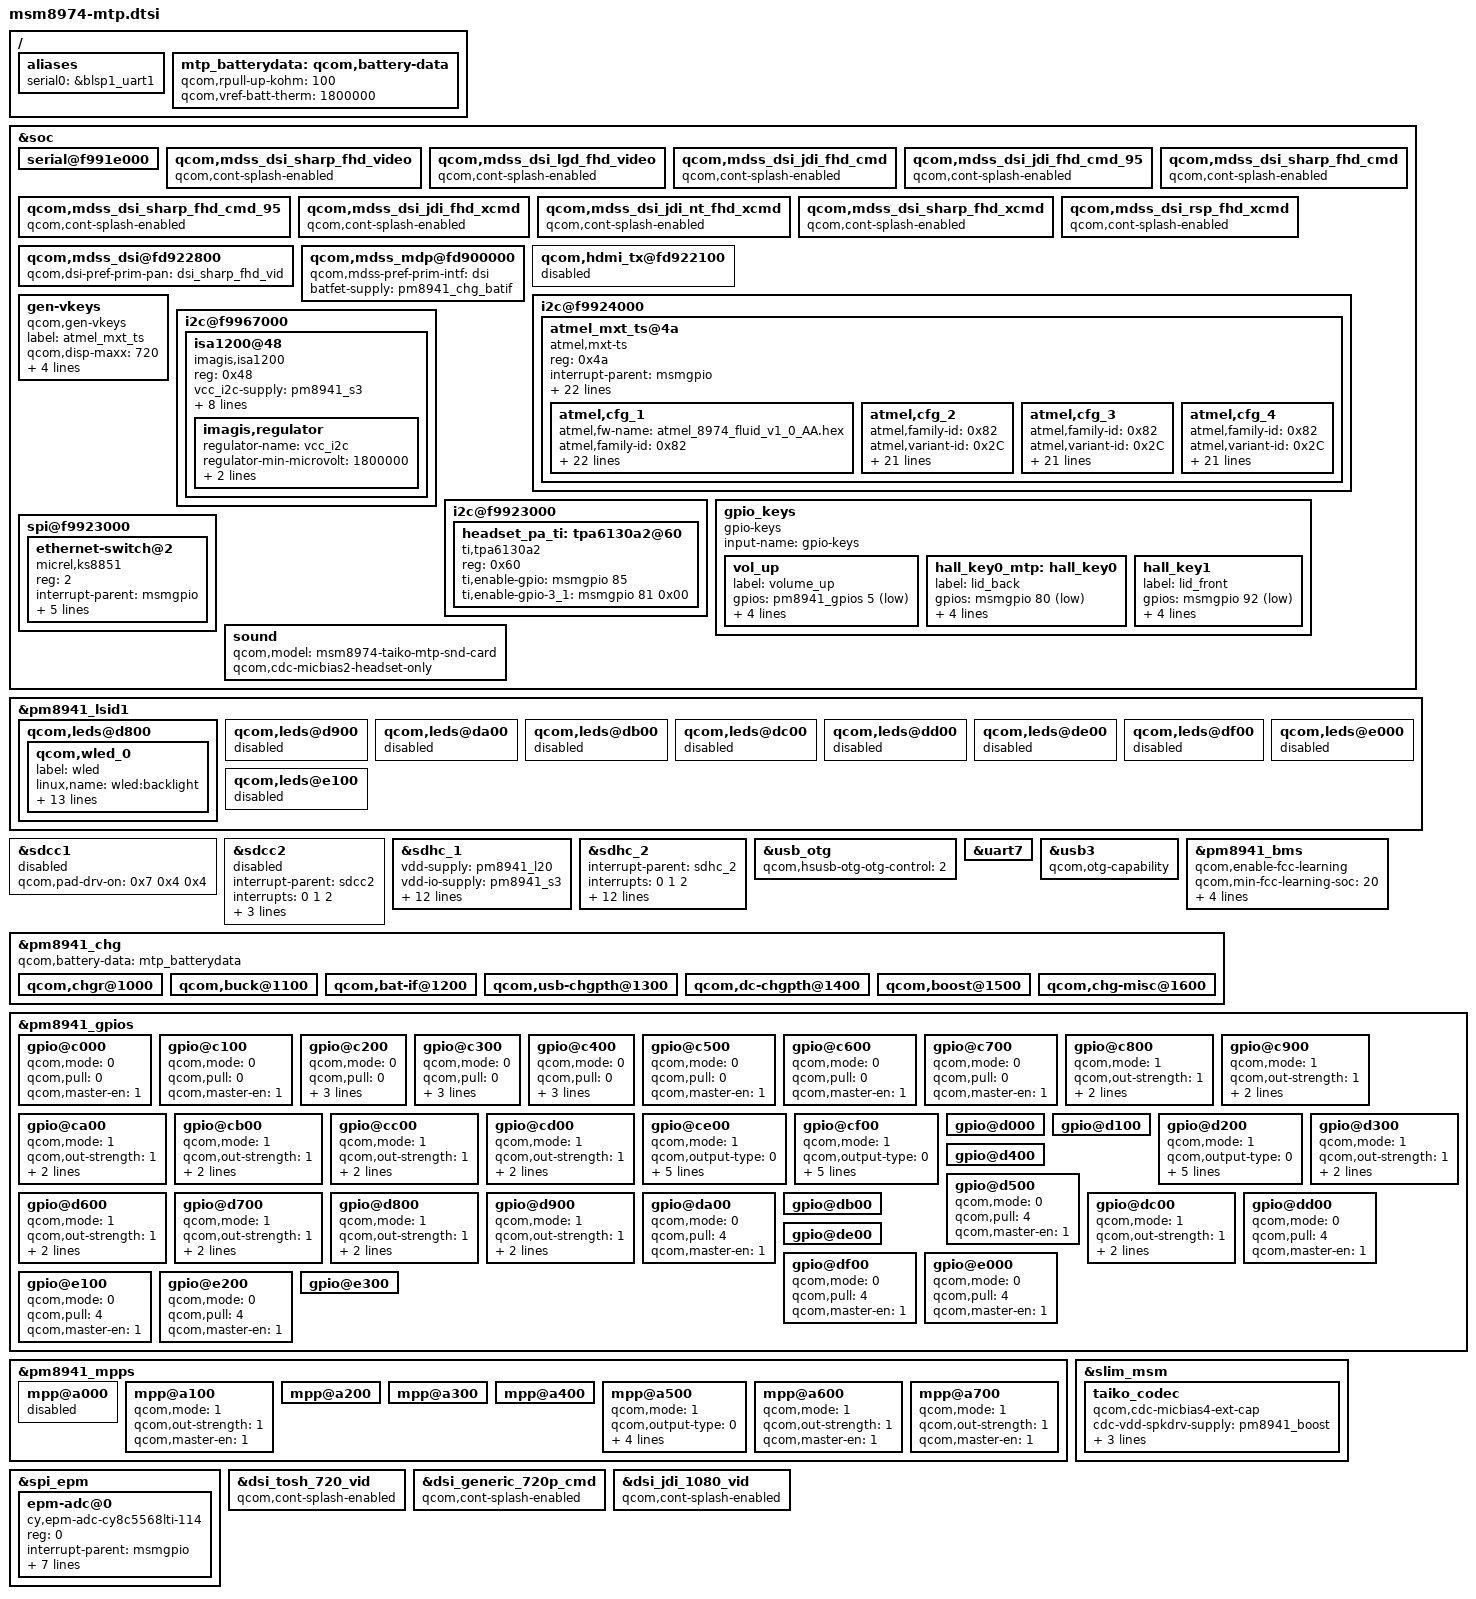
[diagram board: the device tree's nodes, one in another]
/* Copyright (c) 2012-2014, The Linux Foundation. All rights reserved.
 * Copyright (C) 2015 XiaoMi, Inc.
 *
 * This program is free software; you can redistribute it and/or modify
 * it under the terms of the GNU General Public License version 2 and
 * only version 2 as published by the Free Software Foundation.
 *
 * This program is distributed in the hope that it will be useful,
 * but WITHOUT ANY WARRANTY; without even the implied warranty of
 * MERCHANTABILITY or FITNESS FOR A PARTICULAR PURPOSE.  See the
 * GNU General Public License for more details.
 */

/include/ "msm8974-camera-sensor-mtp.dtsi"
/include/ "msm8974-leds.dtsi"

/ {
	aliases {
		serial0 = &blsp1_uart1;
	};
};

&soc {
	serial@f991e000 {
		status = "ok";
	};

	qcom,mdss_dsi_sharp_fhd_video {
		status = "ok";
		qcom,cont-splash-enabled;
	};

	qcom,mdss_dsi_lgd_fhd_video {
		status = "ok";
		qcom,cont-splash-enabled;
	};

	qcom,mdss_dsi_jdi_fhd_cmd {
		status = "ok";
		qcom,cont-splash-enabled;
	};

	qcom,mdss_dsi_jdi_fhd_cmd_95 {
		status = "ok";
		qcom,cont-splash-enabled;
	};

	qcom,mdss_dsi_sharp_fhd_cmd {
		status = "ok";
		qcom,cont-splash-enabled;
	};

	qcom,mdss_dsi_sharp_fhd_cmd_95 {
		status = "ok";
		qcom,cont-splash-enabled;
	};

	qcom,mdss_dsi_jdi_fhd_xcmd {
		status = "ok";
		qcom,cont-splash-enabled;
	};
	qcom,mdss_dsi_jdi_nt_fhd_xcmd {
		status = "ok";
		qcom,cont-splash-enabled;
	};

	qcom,mdss_dsi_sharp_fhd_xcmd {
		status = "ok";
		qcom,cont-splash-enabled;
	};

	qcom,mdss_dsi_rsp_fhd_xcmd {
		status = "ok";
		qcom,cont-splash-enabled;
        };

	qcom,mdss_dsi@fd922800 {
		qcom,dsi-pref-prim-pan = <&dsi_sharp_fhd_vid>;
	};

	qcom,mdss_mdp@fd900000 {
		qcom,mdss-pref-prim-intf = "dsi";
		batfet-supply = <&pm8941_chg_batif>;
	};

	qcom,hdmi_tx@fd922100 {
		status = "disabled";
	};

	i2c@f9924000 {
		atmel_mxt_ts@4a {
			compatible = "atmel,mxt-ts";
			reg = <0x4a>;
			interrupt-parent = <&msmgpio>;
			interrupts = <54 0x2>;
			atmel,reset-gpio = <&msmgpio 60 0x00>;
			atmel,irq-gpio = <&msmgpio 54 0x2008>;
			atmel,power-gpio = <&msmgpio 48 0x00>;
			atmel,mxt-fw-name = "mxT540SC30.fw";
			atmel,unlock-move-threshold = <90000>;
			atmel,staying-threshold = <5>;
			atmel,landing-threshold = <8>;
			atmel,landing-edge-threshold = <28>;
			atmel,landing-jiffies = <1000>;
			atmel,edge-clip = <130>;
			atmel,config-array-size = <4>;
			atmel,irqflags = <0x2008>;
			atmel,gpio-mask = <0x4>;
			atmel,linearity-reg-pos = <11 12 17 18>;
			atmel,linearity-singlex = <10 10 178 50>;
			atmel,linearity-dualx = <24 244 63 51>;
			atmel,linearity-para-num = <4>;
			atmel,rx-num = <18>;
			atmel,tx-num = <30>;
			atmel,ref-diff-threshold = <400>;
			atmel,ref-diff-halfline-threshold = <500>;
			atmel,cfg_1 {
				atmel,fw-name = "atmel_8974_fluid_v1_0_AA.hex";
				atmel,family-id = <0x82>;
				atmel,variant-id = <0x2C>;
				atmel,version = <0x21>;
				atmel,build = <0x00>;
				atmel,mxt-cfg-name = "mxt_double_diamond_config.fw";
				atmel,vendor-id = <0x00>;
				atmel,lcd-id = <0x00>;
				atmel,key-codes = <139 102 158>;
				atmel,key-num = <3>;
				atmel,selfthr-suspend = <0>;
				atmel,selfintthr-stylus = <0>;
				atmel,selfintthr-suspend = <0>;
				atmel,t71-tchthr-pos = <22>;
				atmel,self-no-touch-threshold = <0>;
				atmel,mult-no-touch-threshold = <0>;
				atmel,self-chgtime-min = <0>;
				atmel,self-chgtime-max = <0>;
				atmel,mult-intthr-sensitive = <12>;
				atmel,mult-intthr-not-sensitive = <20>;
				atmel,atchthr-sensitive = <6>;
				atmel,mult-tchthr-sensitive = <0>;
				atmel,mult-tchthr-not-sensitive = <0>;
			};
			atmel,cfg_2 {
				atmel,family-id = <0x82>;
				atmel,variant-id = <0x2C>;
				atmel,version = <0x21>;
				atmel,build = <0x00>;
				atmel,mxt-cfg-name = "mxt_wintek_diamond_config_v20.fw";
				atmel,vendor-id = <0x04>;
				atmel,lcd-id = <0x00>;
				atmel,key-codes = <158 102 139>;
				atmel,key-num = <3>;
				atmel,selfthr-suspend = <0>;
				atmel,selfintthr-stylus = <0>;
				atmel,selfintthr-suspend = <0>;
				atmel,t71-tchthr-pos = <22>;
				atmel,self-no-touch-threshold = <0>;
				atmel,mult-no-touch-threshold = <0>;
				atmel,self-chgtime-min = <0>;
				atmel,self-chgtime-max = <0>;
				atmel,mult-intthr-sensitive = <12>;
				atmel,mult-intthr-not-sensitive = <20>;
				atmel,atchthr-sensitive = <6>;
				atmel,mult-tchthr-sensitive = <0>;
				atmel,mult-tchthr-not-sensitive = <0>;
			};
			atmel,cfg_3 {
				atmel,family-id = <0x82>;
				atmel,variant-id = <0x2C>;
				atmel,version = <0x30>;
				atmel,build = <0xAA>;
				atmel,mxt-cfg-name = "mxt_wintek_diamond_config_v30_sharp.fw";
				atmel,vendor-id = <0x04>;
				atmel,lcd-id = <0x00>;
				atmel,key-codes = <158 102 139>;
				atmel,key-num = <3>;
				atmel,selfthr-suspend = <51>;
				atmel,selfintthr-stylus = <12>;
				atmel,selfintthr-suspend = <8>;
				atmel,t71-tchthr-pos = <22>;
				atmel,self-no-touch-threshold = <220>;
				atmel,mult-no-touch-threshold = <70>;
				atmel,self-chgtime-min = <70>;
				atmel,self-chgtime-max = <100>;
				atmel,mult-intthr-sensitive = <12>;
				atmel,mult-intthr-not-sensitive = <20>;
				atmel,atchthr-sensitive = <6>;
				atmel,mult-tchthr-sensitive = <0x3C>;
				atmel,mult-tchthr-not-sensitive = <0x20>;
			};
			atmel,cfg_4 {
				atmel,family-id = <0x82>;
				atmel,variant-id = <0x2C>;
				atmel,version = <0x30>;
				atmel,build = <0xAA>;
				atmel,mxt-cfg-name = "mxt_wintek_diamond_config_v30_lg.fw";
				atmel,vendor-id = <0x04>;
				atmel,lcd-id = <0x01>;
				atmel,key-codes = <158 102 139>;
				atmel,key-num = <3>;
				atmel,selfthr-suspend = <51>;
				atmel,selfintthr-stylus = <12>;
				atmel,selfintthr-suspend = <8>;
				atmel,t71-tchthr-pos = <22>;
				atmel,self-no-touch-threshold = <220>;
				atmel,mult-no-touch-threshold = <70>;
				atmel,self-chgtime-min = <70>;
				atmel,self-chgtime-max = <100>;
				atmel,mult-intthr-sensitive = <12>;
				atmel,mult-intthr-not-sensitive = <20>;
				atmel,atchthr-sensitive = <6>;
				atmel,mult-tchthr-sensitive = <0x3C>;
				atmel,mult-tchthr-not-sensitive = <0x20>;
			};
		};
	};

	gen-vkeys {
		compatible = "qcom,gen-vkeys";
		label = "atmel_mxt_ts";
		qcom,disp-maxx = <720>;
		qcom,disp-maxy = <1280>;
		qcom,panel-maxx = <760>;
		qcom,panel-maxy = <1424>;
		qcom,key-codes = <158 139 102 217>;
	};

	i2c@f9967000 {
		isa1200@48 {
			status = "okay";
			reg = <0x48>;
			vcc_i2c-supply = <&pm8941_s3>;
			compatible = "imagis,isa1200";
			label = "vibrator";
			imagis,chip-en;
			imagis,need-pwm-clk;
			imagis,ext-clk-en;
			imagis,hap-en-gpio = <&msmgpio 86 0x00>;
			imagis,max-timeout = <15000>;
			imagis,pwm-div = <256>;
			imagis,mode-ctrl = <2>;
			imagis,regulator {
				regulator-name = "vcc_i2c";
				regulator-min-microvolt = <1800000>;
				regulator-max-microvolt = <1800000>;
				regulator-max-microamp = <9360>;
			};
		};
	};

	i2c@f9923000 {
		headset_pa_ti: tpa6130a2@60 {
			reg = <0x60>;
			compatible = "ti,tpa6130a2";
			ti,enable-gpio = <&msmgpio 85 0x00>;
			ti,enable-gpio-3_1 = <&msmgpio 81 0x00>;
		};
	};

	gpio_keys {
		compatible = "gpio-keys";
		input-name = "gpio-keys";
		vol_up {
			label = "volume_up";
			gpios = <&pm8941_gpios 5 0x1>;
			linux,input-type = <1>;
			linux,code = <115>;
			gpio-key,wakeup;
			debounce-interval = <15>;
		};
		hall_key0_mtp: hall_key0 {
			label = "lid_back";
			gpios = <&msmgpio 80 0x01>;
			linux,input-type = <5>;
			linux,code = <18>;
			gpio-key,wakeup;
			debounce-interval = <15>;
		};
		hall_key1 {
			label = "lid_front";
			gpios = <&msmgpio 92 0x01>;
			linux,input-type = <5>;
			linux,code = <0>;
			gpio-key,wakeup;
			debounce-interval = <15>;
		};


	};

	spi@f9923000 {
		ethernet-switch@2 {
			compatible = "micrel,ks8851";
			reg = <2>;
			interrupt-parent = <&msmgpio>;
			interrupts = <94 0>;
			spi-max-frequency = <4800000>;
			rst-gpio = <&pm8941_mpps 6 0>;
			vdd-io-supply = <&spi_eth_vreg>;
			vdd-phy-supply = <&spi_eth_vreg>;
		};
	};

	sound {
		qcom,model = "msm8974-taiko-mtp-snd-card";
		qcom,cdc-micbias2-headset-only;
	};
};

&pm8941_lsid1 {
	qcom,leds@d800 {
		status = "okay";
		qcom,wled_0 {
			label = "wled";
			linux,name = "wled:backlight";
			linux,default-trigger = "bkl-trigger";
			qcom,cs-out-en;
			qcom,op-fdbck = <1>;
			qcom,cabc-en;
			qcom,default-state = "on";
			qcom,max-current = <23>;
			qcom,ctrl-delay-us = <0>;
			qcom,boost-curr-lim = <5>;
			qcom,cp-sel = <0>;
			qcom,switch-freq = <11>;
			qcom,ovp-val = <2>;
			qcom,num-strings = <2>;
			qcom,id = <0>;
		};
	};

	qcom,leds@d900 {
		status = "disabled";
	};

	qcom,leds@da00 {
		status = "disabled";
	};

	qcom,leds@db00 {
		status = "disabled";
	};

	qcom,leds@dc00 {
		status = "disabled";
	};

	qcom,leds@dd00 {
		status = "disabled";
	};

	qcom,leds@de00 {
		status = "disabled";
	};

	qcom,leds@df00 {
		status = "disabled";
	};

	qcom,leds@e000 {
		status = "disabled";
	};

	qcom,leds@e100 {
		status = "disabled";
	};
};

&sdcc1 {
       status = "disabled";
};

&sdcc2 {
	#address-cells = <0>;
	interrupt-parent = <&sdcc2>;
	interrupts = <0 1 2>;
	#interrupt-cells = <1>;
	interrupt-map-mask = <0xffffffff>;
	interrupt-map = <0 &intc 0 125 0
			1 &intc 0 220 0>;
	interrupt-names = "core_irq", "bam_irq", "status_irq";
	status = "disabled";
};

&sdhc_1 {
	vdd-supply = <&pm8941_l20>;
	vdd-io-supply = <&pm8941_s3>;

	qcom,vdd-always-on;
	qcom,vdd-lpm-sup;
	qcom,vdd-voltage-level = <2950000 2950000>;
	qcom,vdd-current-level = <800 500000>;

	qcom,vdd-io-always-on;
	qcom,vdd-io-voltage-level = <1800000 1800000>;
	qcom,vdd-io-current-level = <250 154000>;

	qcom,pad-pull-on = <0x0 0x3 0x3>; /* no-pull, pull-up, pull-up */
	qcom,pad-pull-off = <0x0 0x3 0x3>; /* no-pull, pull-up, pull-up */
	qcom,pad-drv-on = <0x4 0x4 0x4>; /* 10mA, 10mA, 10mA */
	qcom,pad-drv-off = <0x0 0x0 0x0>; /* 2mA, 2mA, 2mA */

	qcom,nonremovable;
	status = "ok";
};

&sdhc_2 {
	#address-cells = <0>;
	interrupt-parent = <&sdhc_2>;
	interrupts = <0 1 2>;
	#interrupt-cells = <1>;
	interrupt-map-mask = <0xffffffff>;
	interrupt-map = <0 &intc 0 125 0
			1 &intc 0 221 0>;
	interrupt-names = "hc_irq", "pwr_irq", "status_irq";

	vdd-supply = <&pm8941_l21>;
	vdd-io-supply = <&pm8941_l13>;

	qcom,vdd-voltage-level = <2950000 2950000>;
	qcom,vdd-current-level = <9000 800000>;

	qcom,vdd-io-voltage-level = <1800000 2950000>;
	qcom,vdd-io-current-level = <6 22000>;

	qcom,pad-pull-on = <0x0 0x3 0x3>; /* no-pull, pull-up, pull-up */
	qcom,pad-pull-off = <0x0 0x3 0x3>; /* no-pull, pull-up, pull-up */
	qcom,pad-drv-on = <0x4 0x4 0x4>; /* 10mA, 10mA, 10mA */
	qcom,pad-drv-off = <0x0 0x0 0x0>; /* 2mA, 2mA, 2mA */
	status = "ok";
};

/* Drive strength recommendations for clock line from hardware team is 10 mA.
 * But since the driver has been been using the below values from the start
 * without any problems, continue to use those.
 */
&sdcc1 {
	qcom,pad-drv-on = <0x7 0x4 0x4>; /* 16mA, 10mA, 10mA */
};

&sdcc2 {
	qcom,pad-drv-on = <0x7 0x4 0x4>; /* 16mA, 10mA, 10mA */
};

&sdhc_1 {
	qcom,pad-drv-on = <0x7 0x4 0x4>; /* 16mA, 10mA, 10mA */
};

&sdhc_2 {
	qcom,pad-drv-on = <0x7 0x4 0x4>; /* 16mA, 10mA, 10mA */
};

&usb_otg {
	qcom,hsusb-otg-otg-control = <2>;
};

&uart7 {
	status = "ok";
};

&usb3 {
	qcom,otg-capability;
};

/ {
	mtp_batterydata: qcom,battery-data {
		qcom,rpull-up-kohm = <100>;
		qcom,vref-batt-therm = <1800000>;

		/include/ "batterydata-BM31-SDI-2980mAh.dtsi"
		/include/ "batterydata-BM31-SONY-2980mAh.dtsi"
		/include/ "batterydata-BM31-LG-2980mAh.dtsi"
		/include/ "batterydata-BM31-SDI-3020mAh.dtsi"
		/include/ "batterydata-BM31-SDI1-3020mAh.dtsi"
		/include/ "batterydata-BM31-SONY-3020mAh.dtsi"
		/include/ "batterydata-BM31-LG-3020mAh.dtsi"
		/include/ "batterydata-BM31-SDI-3080mAh.dtsi"
		/include/ "batterydata-BM31-LG-3080mAh.dtsi"
		/include/ "batterydata-BM31-LG-3080mAh-44V.dtsi"
		/include/ "batterydata-BM31-SONY-3080mAh-44V.dtsi"
	};
};

&pm8941_bms {
	qcom,enable-fcc-learning;
	qcom,min-fcc-learning-soc = <20>;
	qcom,min-fcc-ocv-pc = <30>;
	qcom,min-fcc-learning-samples = <5>;
	qcom,fcc-resolution = <10>;
	status = "ok";
	qcom,battery-data = <&mtp_batterydata>;
};

&pm8941_chg {
	status = "ok";
	qcom,battery-data = <&mtp_batterydata>;

	qcom,chgr@1000 {
		status = "ok";
	};

	qcom,buck@1100 {
		status = "ok";
	};

	qcom,bat-if@1200 {
		status = "ok";
	};

	qcom,usb-chgpth@1300 {
		status = "ok";
	};

	qcom,dc-chgpth@1400 {
		status = "ok";
	};

	qcom,boost@1500 {
		status = "ok";
	};

	qcom,chg-misc@1600 {
		status = "ok";
	};
};

&pm8941_gpios {
	gpio@c000 { /* GPIO 1 */
		qcom,mode = <0>;        /* QPNP_PIN_MODE_DIG_IN */
		qcom,pull = <0>;        /* QPNP_PIN_PULL_UP_30  */
		qcom,master-en = <1>;
	};

	gpio@c100 { /* GPIO 2 */
		qcom,mode = <0>;        /* QPNP_PIN_MODE_DIG_IN */
		qcom,pull = <0>;        /* QPNP_PIN_PULL_UP_30  */
		qcom,master-en = <1>;
	};

	gpio@c200 { /* GPIO 3 */
		qcom,mode = <0>;        /* QPNP_PIN_MODE_DIG_IN */
		qcom,pull = <0>;        /* QPNP_PIN_PULL_UP_30  */
		qcom,vin-sel = <2>;
		qcom,src-sel = <0>;	/* QPNP_PIN_SEL_FUNC_CONSTANT */
		qcom,master-en = <1>;
	};

	gpio@c300 { /* GPIO 4 */
		qcom,mode = <0>;        /* QPNP_PIN_MODE_DIG_IN */
		qcom,pull = <0>;        /* QPNP_PIN_PULL_UP_30  */
		qcom,vin-sel = <2>;     /* QPNP_PIN_VIN2  */
		qcom,src-sel = <0>;	/* QPNP_PIN_SEL_FUNC_CONSTANT */
		qcom,master-en = <1>;
	};

	gpio@c400 { /* GPIO 5 */
		qcom,mode = <0>;        /* QPNP_PIN_MODE_DIG_IN */
		qcom,pull = <0>;        /* QPNP_PIN_PULL_UP_30  */
		qcom,vin-sel = <2>;     /* QPNP_PIN_VIN2  */
		qcom,src-sel = <0>;	/* QPNP_PIN_SEL_FUNC_CONSTANT */
		qcom,master-en = <1>;
	};

	gpio@c500 { /* GPIO 6 */
		qcom,mode = <0>;        /* QPNP_PIN_MODE_DIG_IN */
		qcom,pull = <0>;        /* QPNP_PIN_PULL_UP_30  */
		qcom,master-en = <1>;
	};

	gpio@c600 { /* GPIO 7 */
		qcom,mode = <0>;        /* QPNP_PIN_MODE_DIG_IN */
		qcom,pull = <0>;        /* QPNP_PIN_PULL_UP_30  */
		qcom,master-en = <1>;
	};

	gpio@c700 { /* GPIO 8 */
		qcom,mode = <0>;        /* QPNP_PIN_MODE_DIG_IN */
		qcom,pull = <0>;        /* QPNP_PIN_PULL_UP_30  */
		qcom,master-en = <1>;
	};

	gpio@c800 { /* GPIO 9 */
		qcom,mode = <1>;          /* QPNP_PIN_MODE_DIG_OUT */
		qcom,out-strength = <1>;  /* QPNP_PIN_OUT_STRENGTH_LOW */
		qcom,src-sel = <2>;       /* QPNP_PIN_SEL_FUNC_1  */
		qcom,master-en = <1>;
	};

	gpio@c900 { /* GPIO 10 */
		qcom,mode = <1>;          /* QPNP_PIN_MODE_DIG_OUT */
		qcom,out-strength = <1>;  /* QPNP_PIN_OUT_STRENGTH_LOW */
		qcom,src-sel = <2>;       /* QPNP_PIN_SEL_FUNC_1  */
		qcom,master-en = <1>;
	};

	gpio@ca00 { /* GPIO 11 */
		qcom,mode = <1>;          /* QPNP_PIN_MODE_DIG_OUT */
		qcom,out-strength = <1>;  /* QPNP_PIN_OUT_STRENGTH_LOW */
		qcom,src-sel = <2>;       /* QPNP_PIN_SEL_FUNC_1  */
		qcom,master-en = <1>;
	};

	gpio@cb00 { /* GPIO 12 */
		qcom,mode = <1>;          /* QPNP_PIN_MODE_DIG_OUT */
		qcom,out-strength = <1>;  /* QPNP_PIN_OUT_STRENGTH_LOW */
		qcom,src-sel = <2>;       /* QPNP_PIN_SEL_FUNC_1  */
		qcom,master-en = <1>;
	};

	gpio@cc00 { /* GPIO 13 */
		qcom,mode = <1>;          /* QPNP_PIN_MODE_DIG_OUT */
		qcom,out-strength = <1>;  /* QPNP_PIN_OUT_STRENGTH_LOW */
		qcom,src-sel = <2>;       /* QPNP_PIN_SEL_FUNC_1  */
		qcom,master-en = <1>;
	};

	gpio@cd00 { /* GPIO 14 */
		qcom,mode = <1>;          /* QPNP_PIN_MODE_DIG_OUT */
		qcom,out-strength = <1>;  /* QPNP_PIN_OUT_STRENGTH_LOW */
		qcom,src-sel = <2>;       /* QPNP_PIN_SEL_FUNC_1  */
		qcom,master-en = <1>;
	};

	gpio@ce00 { /* GPIO 15 */
		qcom,mode = <1>;
		qcom,output-type = <0>;
		qcom,pull = <5>;
		qcom,vin-sel = <2>;
		qcom,out-strength = <1>;
		qcom,src-sel = <2>;
		qcom,master-en = <1>;
	};

	gpio@cf00 { /* GPIO 16 */
		qcom,mode = <1>;
		qcom,output-type = <0>;
		qcom,pull = <5>;
		qcom,vin-sel = <2>;
		qcom,out-strength = <3>;
		qcom,src-sel = <3>;       /* QPNP_PIN_SEL_FUNC_2  */
		qcom,master-en = <1>;
	};

	gpio@d000 { /* GPIO 17 */
	};

	gpio@d100 { /* GPIO 18 */
	};

	gpio@d200 { /* GPIO 19 */
		qcom,mode = <1>;		/* QPNP_PIN_MODE_DIG_OUT */
		qcom,output-type = <0>;		/* QPNP_PIN_OUT_BUF_CMOS */
		qcom,pull = <5>;		/* QPNP_PIN_PULL_NO */
		qcom,vin-sel = <2>;		/* QPNP_PIN_VIN2 */
		qcom,out-strength = <1>;	/* QPNP_PIN_OUT_STRENGTH_LOW */
		qcom,src-sel = <0>;		/* QPNP_PIN_SEL_FUNC_CONSTANT */
		qcom,master-en = <1>;
	};

	gpio@d300 { /* GPIO 20 */
		qcom,mode = <1>;          /* QPNP_PIN_MODE_DIG_OUT */
		qcom,out-strength = <1>;  /* QPNP_PIN_OUT_STRENGTH_LOW */
		qcom,src-sel = <2>;       /* QPNP_PIN_SEL_FUNC_1  */
		qcom,master-en = <1>;
	};

	gpio@d400 { /* GPIO 21 */
	};

	gpio@d500 { /* GPIO 22 */
		qcom,mode = <0>;        /* QPNP_PIN_MODE_DIG_IN */
		qcom,pull = <4>;	/* QPNP_PIN_PULL_DN */
		qcom,master-en = <1>;
	};

	gpio@d600 { /* GPIO 23 */
		qcom,mode = <1>;          /* QPNP_PIN_MODE_DIG_OUT */
		qcom,out-strength = <1>;  /* QPNP_PIN_OUT_STRENGTH_LOW */
		qcom,src-sel = <2>;       /* QPNP_PIN_SEL_FUNC_1  */
		qcom,master-en = <1>;
	};

	gpio@d700 { /* GPIO 24 */
		qcom,mode = <1>;          /* QPNP_PIN_MODE_DIG_OUT */
		qcom,out-strength = <1>;  /* QPNP_PIN_OUT_STRENGTH_LOW */
		qcom,src-sel = <2>;       /* QPNP_PIN_SEL_FUNC_1  */
		qcom,master-en = <1>;
	};

	gpio@d800 { /* GPIO 25 */
		qcom,mode = <1>;          /* QPNP_PIN_MODE_DIG_OUT */
		qcom,out-strength = <1>;  /* QPNP_PIN_OUT_STRENGTH_LOW */
		qcom,src-sel = <2>;       /* QPNP_PIN_SEL_FUNC_1  */
		qcom,master-en = <1>;
	};

	gpio@d900 { /* GPIO 26 */
		qcom,mode = <1>;          /* QPNP_PIN_MODE_DIG_OUT */
		qcom,out-strength = <1>;  /* QPNP_PIN_OUT_STRENGTH_LOW */
		qcom,src-sel = <2>;       /* QPNP_PIN_SEL_FUNC_1  */
		qcom,master-en = <1>;
	};

	gpio@da00 { /* GPIO 27 */
		qcom,mode = <0>;        /* QPNP_PIN_MODE_DIG_IN */
		qcom,pull = <4>;	/* QPNP_PIN_PULL_DN */
		qcom,master-en = <1>;
	};

	gpio@db00 { /* GPIO 28 */
	};

	gpio@dc00 { /* GPIO 29 */
		qcom,mode = <1>;          /* QPNP_PIN_MODE_DIG_OUT */
		qcom,out-strength = <1>;  /* QPNP_PIN_OUT_STRENGTH_LOW */
		qcom,src-sel = <2>;       /* QPNP_PIN_SEL_FUNC_1  */
		qcom,master-en = <1>;
	};

	gpio@dd00 { /* GPIO 30 */
		qcom,mode = <0>;        /* QPNP_PIN_MODE_DIG_IN */
		qcom,pull = <4>;	/* QPNP_PIN_PULL_DN */
		qcom,master-en = <1>;
	};

	gpio@de00 { /* GPIO 31 */
	};

	gpio@df00 { /* GPIO 32 */
		qcom,mode = <0>;        /* QPNP_PIN_MODE_DIG_IN */
		qcom,pull = <4>;	/* QPNP_PIN_PULL_DN */
		qcom,master-en = <1>;
	};

	gpio@e000 { /* GPIO 33 */
		qcom,mode = <0>;        /* QPNP_PIN_MODE_DIG_IN */
		qcom,pull = <4>;	/* QPNP_PIN_PULL_DN */
		qcom,master-en = <1>;
	};

	gpio@e100 { /* GPIO 34 */
		qcom,mode = <0>;        /* QPNP_PIN_MODE_DIG_IN */
		qcom,pull = <4>;	/* QPNP_PIN_PULL_DN */
		qcom,master-en = <1>;
	};

	gpio@e200 { /* GPIO 35 */
		qcom,mode = <0>;        /* QPNP_PIN_MODE_DIG_IN */
		qcom,pull = <4>;	/* QPNP_PIN_PULL_DN */
		qcom,master-en = <1>;
	};

	gpio@e300 { /* GPIO 36 */
	};
};

&pm8941_mpps {

	mpp@a000 { /* MPP 1 */
		status = "disabled";
	};

	mpp@a100 { /* MPP 2 */
		qcom,mode = <1>;          /* QPNP_PIN_MODE_DIG_OUT */
		qcom,out-strength = <1>;  /* QPNP_PIN_OUT_STRENGTH_LOW */
		qcom,master-en = <1>;
	};

	mpp@a200 { /* MPP 3 */
	};

	mpp@a300 { /* MPP 4 */
	};

	mpp@a400 { /* MPP 5 */
	};

	mpp@a500 { /* MPP 6 */
		/* SPI_ETH_RST config */
		qcom,mode = <1>; /* DIG_OUT */
		qcom,output-type = <0>; /* CMOS */
		qcom,vin-sel = <2>; /* PM8941_S3 1.8V > 1.6V */
		qcom,src-sel = <0>; /* CONSTANT */
		qcom,out-strength = <1>;  /* QPNP_PIN_OUT_STRENGTH_LOW */
		qcom,master-en = <1>; /* ENABLE MPP */
	};

	mpp@a600 { /* MPP 7 */
		qcom,mode = <1>;          /* QPNP_PIN_MODE_DIG_OUT */
		qcom,out-strength = <1>;  /* QPNP_PIN_OUT_STRENGTH_LOW */
		qcom,master-en = <1>;
	};

	mpp@a700 { /* MPP 8 */
		qcom,mode = <1>;          /* QPNP_PIN_MODE_DIG_OUT */
		qcom,out-strength = <1>;  /* QPNP_PIN_OUT_STRENGTH_LOW */
		qcom,master-en = <1>;
	};
};

&slim_msm {
	taiko_codec {
		/*qcom,cdc-micbias1-ext-cap;*/
		/*qcom,cdc-micbias2-ext-cap;*/
		qcom,cdc-micbias4-ext-cap;

		/* If boot isn't available, vph_pwr_vreg can be used instead */
		cdc-vdd-spkdrv-supply = <&pm8941_boost>;
		qcom,cdc-vdd-spkdrv-voltage = <5000000 5000000>;
		qcom,cdc-vdd-spkdrv-current = <1250000>;

		qcom,cdc-on-demand-supplies = "cdc-vdd-spkdrv";
	};
};

&spi_epm {
	epm-adc@0 {
		compatible = "cy,epm-adc-cy8c5568lti-114";
		reg = <0>;
		interrupt-parent = <&msmgpio>;
		spi-max-frequency = <960000>;
		qcom,channels = <31>;
		qcom,gain = <100 100 100 50 100 100 1 100 1 50
				1 100 1 100 50 50 50 50 50 50
				100 50 100 50 50 50 50 50 50 50
				50>;
		qcom,rsense = <2 2 2 200 20 2 1 2 1 30
				1 10 1 30 50 30 500 30 100 30
				100 500 20 200 1000 20 1000 1000 70 200
				50>;
		qcom,channel-type = <0x1540>;
	};
};

&dsi_tosh_720_vid {
       qcom,cont-splash-enabled;
};

&dsi_generic_720p_cmd {
       qcom,cont-splash-enabled;
};

&dsi_jdi_1080_vid {
       qcom,cont-splash-enabled;
};
